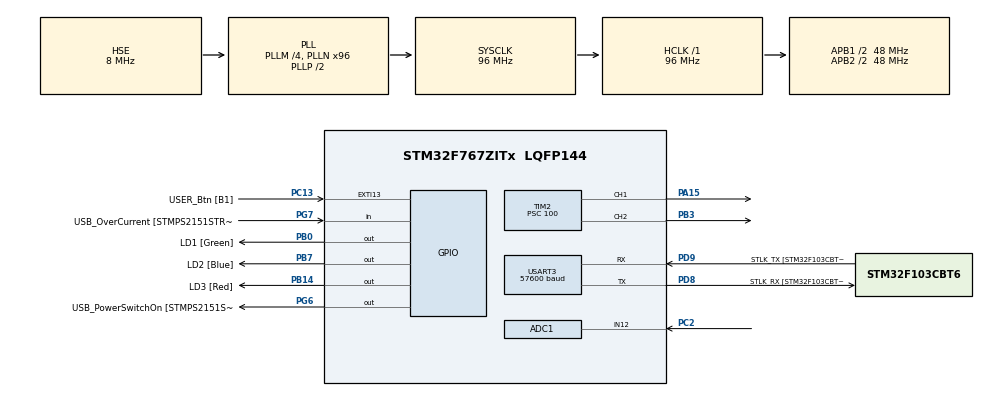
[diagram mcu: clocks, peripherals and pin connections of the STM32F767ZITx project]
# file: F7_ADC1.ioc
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ADC1.Channel-0\#ChannelRegularConversion=ADC_CHANNEL_12
ADC1.Channel-1\#ChannelRegularConversion=ADC_CHANNEL_TEMPSENSOR
ADC1.DMAContinuousRequests=ENABLE
ADC1.EOCSelection=ADC_EOC_SEQ_CONV
ADC1.ExternalTrigConv=ADC_EXTERNALTRIGCONV_T1_TRGO
ADC1.NbrOfConversion=2
ADC1.NbrOfConversionFlag=1
ADC1.Rank-0\#ChannelRegularConversion=1
ADC1.Rank-1\#ChannelRegularConversion=2
ADC1.SamplingTime-0\#ChannelRegularConversion=ADC_SAMPLETIME_480CYCLES
ADC1.SamplingTime-1\#ChannelRegularConversion=ADC_SAMPLETIME_480CYCLES
ADC1.master=1
Dma.ADC1.0.Direction=DMA_PERIPH_TO_MEMORY
Dma.ADC1.0.FIFOMode=DMA_FIFOMODE_DISABLE
Dma.ADC1.0.Instance=DMA2_Stream0
Dma.ADC1.0.MemDataAlignment=DMA_MDATAALIGN_WORD
Dma.ADC1.0.MemInc=DMA_MINC_ENABLE
Dma.ADC1.0.Mode=DMA_CIRCULAR
Dma.ADC1.0.PeriphDataAlignment=DMA_PDATAALIGN_WORD
Dma.ADC1.0.PeriphInc=DMA_PINC_DISABLE
Dma.ADC1.0.Priority=DMA_PRIORITY_LOW
Dma.Request0=ADC1
Mcu.Family=STM32F7
Mcu.Name=STM32F767ZITx
Mcu.Package=LQFP144
NVIC.DMA2_Stream0_IRQn=true\:0\:0\:false\:false\:true\:false\:true\:true
NVIC.PriorityGroup=NVIC_PRIORITYGROUP_4
NVIC.USART3_IRQn=true\:0\:0\:false\:false\:true\:true\:true\:true
PA13.GPIO_Label=TMS
PA13.Mode=Serial_Wire
PA13.Signal=SYS_JTMS-SWDIO
PA14.GPIO_Label=TCK
PA14.Mode=Serial_Wire
PA14.Signal=SYS_JTCK-SWCLK
PA15.Signal=S_TIM2_CH1_ETR
PB0.GPIO_Label=LD1 [Green]
PB0.Signal=GPIO_Output
PB14.GPIO_Label=LD3 [Red]
PB14.Signal=GPIO_Output
PB3.Signal=S_TIM2_CH2
PB7.GPIO_Label=LD2 [Blue]
PB7.Signal=GPIO_Output
PC13.GPIO_Label=USER_Btn [B1]
PC13.Signal=GPXTI13
PC14/OSC32_IN.Mode=LSE-External-Oscillator
PC14/OSC32_IN.Signal=RCC_OSC32_IN
PC15/OSC32_OUT.Mode=LSE-External-Oscillator
PC15/OSC32_OUT.Signal=RCC_OSC32_OUT
PC2.Signal=ADCx_IN12
PD8.GPIO_Label=STLK_RX [STM32F103CBT6_PA3]
PD8.Mode=Asynchronous
PD8.Signal=USART3_TX
PD9.GPIO_Label=STLK_TX [STM32F103CBT6_PA2]
PD9.Mode=Asynchronous
PD9.Signal=USART3_RX
PG6.GPIO_Label=USB_PowerSwitchOn [STMPS2151STR_EN]
PG6.Signal=GPIO_Output
PG7.GPIO_Label=USB_OverCurrent [STMPS2151STR_FAULT]
PG7.Signal=GPIO_Input
PH0/OSC_IN.GPIO_Label=MCO [STM32F103CBT6_PA8]
PH0/OSC_IN.Mode=HSE-External-Clock-Source
PH0/OSC_IN.Signal=RCC_OSC_IN
PH1/OSC_OUT.Mode=HSE-External-Clock-Source
PH1/OSC_OUT.Signal=RCC_OSC_OUT
ProjectManager.HeapSize=0x200
ProjectManager.StackSize=0x400
ProjectManager.TargetToolchain=STM32CubeIDE
RCC.48MHZClocksFreq_Value=24000000
RCC.AHBFreq_Value=96000000
RCC.APB1CLKDivider=RCC_HCLK_DIV2
RCC.APB1Freq_Value=48000000
RCC.APB1TimFreq_Value=96000000
RCC.APB2CLKDivider=RCC_HCLK_DIV2
RCC.APB2Freq_Value=48000000
RCC.APB2TimFreq_Value=96000000
RCC.CortexFreq_Value=96000000
RCC.HCLKFreq_Value=96000000
RCC.HSE_VALUE=8000000
RCC.HSI_VALUE=16000000
RCC.PLLM=4
RCC.PLLMUL=RCC_PLL_MUL9
RCC.PLLN=96
RCC.PLLQ=4
RCC.PLLSourceVirtual=RCC_PLLSOURCE_HSE
RCC.PRESCALERUSB=RCC_USBCLKSOURCE_PLL_DIV1_5
RCC.SYSCLKFreq_VALUE=96000000
RCC.SYSCLKSource=RCC_SYSCLKSOURCE_PLLCLK
RCC.SYSCLKSourceVirtual=RCC_SYSCLKSOURCE_PLLCLK
RCC.USBFreq_Value=48000000
RCC.VCOOutputFreq_Value=192000000
SH.ADCx_IN12.0=ADC1_IN12,IN12
SH.S_TIM2_CH1_ETR.0=TIM2_CH1,PWM Generation1 CH1
SH.S_TIM2_CH2.0=TIM2_CH2,PWM Generation2 CH2
TIM1.Channel-Output\ Compare1\ No\ Output=TIM_CHANNEL_1
TIM1.Period=49
TIM1.Prescaler=48000
TIM1.TIM_MasterOutputTrigger=TIM_TRGO_UPDATE
TIM2.AutoReloadPreload=TIM_AUTORELOAD_PRELOAD_DISABLE
TIM2.Channel-PWM\ Generation1\ CH1=TIM_CHANNEL_1
TIM2.Channel-PWM\ Generation2\ CH2=TIM_CHANNEL_2
TIM2.OC1Preload_PWM=DISABLE
TIM2.OC2Preload_PWM=DISABLE
TIM2.OCFastMode_PWM-PWM\ Generation1\ CH1=TIM_OCFAST_DISABLE
TIM2.OCFastMode_PWM-PWM\ Generation2\ CH2=TIM_OCFAST_DISABLE
TIM2.Period=999
TIM2.Prescaler=100
TIM2.Pulse-PWM\ Generation1\ CH1=0
TIM2.Pulse-PWM\ Generation2\ CH2=0
USART3.BaudRate=57600
USART3.VirtualMode-Asynchronous=VM_ASYNC
VP_ADC1_TempSens_Input.Mode=IN-TempSens
VP_TIM1_VS_ClockSourceINT.Mode=Internal
VP_TIM1_VS_no_output1.Mode=Output Compare1 No Output
VP_TIM2_VS_ClockSourceINT.Mode=Internal
board=NUCLEO-F767ZI

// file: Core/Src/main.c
/* USER CODE BEGIN Header */
/**
  ******************************************************************************
  * @file           : main.c
  * @brief          : Main program body
  ******************************************************************************
  * @attention
  *
  * Copyright (c) 2023 STMicroelectronics.
  * All rights reserved.
  *
  * This software is licensed under terms that can be found in the LICENSE file
  * in the root directory of this software component.
  * If no LICENSE file comes with this software, it is provided AS-IS.
  *
  ******************************************************************************
  */
/* USER CODE END Header */
#include "main.h"
#include "adc.h"
#include "dma.h"
#include "tim.h"
#include "usart.h"
#include "gpio.h"

/* USER CODE BEGIN Includes */
#include <stdio.h>
#include <string.h>

#include "app_interface.h"

/* USER CODE END Includes */

void SystemClock_Config(void);

int main(void)
{

  /* MCU Configuration--------------------------------------------------------*/

  /* Reset of all peripherals, Initializes the Flash interface and the Systick. */
  HAL_Init();

  /* Configure the system clock */
  SystemClock_Config();

  /* Initialize all configured peripherals */
  MX_GPIO_Init();
  MX_DMA_Init();
  MX_USART3_UART_Init();
  MX_ADC1_Init();
  MX_TIM1_Init();
  MX_TIM2_Init();
  /* USER CODE BEGIN 2 */
  noreturn_app();
  /* USER CODE END 2 */

  /* Infinite loop */
  while (1)
  {

  }
}

void SystemClock_Config(void)
{
  RCC_OscInitTypeDef RCC_OscInitStruct = {0};
  RCC_ClkInitTypeDef RCC_ClkInitStruct = {0};

  /** Configure LSE Drive Capability
  */
  HAL_PWR_EnableBkUpAccess();

  /** Configure the main internal regulator output voltage
  */
  __HAL_RCC_PWR_CLK_ENABLE();
  __HAL_PWR_VOLTAGESCALING_CONFIG(PWR_REGULATOR_VOLTAGE_SCALE3);

  /** Initializes the RCC Oscillators according to the specified parameters
  * in the RCC_OscInitTypeDef structure.
  */
  RCC_OscInitStruct.OscillatorType = RCC_OSCILLATORTYPE_HSE;
  RCC_OscInitStruct.HSEState = RCC_HSE_BYPASS;
  RCC_OscInitStruct.PLL.PLLState = RCC_PLL_ON;
  RCC_OscInitStruct.PLL.PLLSource = RCC_PLLSOURCE_HSE;
  RCC_OscInitStruct.PLL.PLLM = 4;
  RCC_OscInitStruct.PLL.PLLN = 96;
  RCC_OscInitStruct.PLL.PLLP = RCC_PLLP_DIV2;
  RCC_OscInitStruct.PLL.PLLQ = 4;
  RCC_OscInitStruct.PLL.PLLR = 2;
  if (HAL_RCC_OscConfig(&RCC_OscInitStruct) != HAL_OK)
  {
    Error_Handler();
  }

  /** Activate the Over-Drive mode
  */
  if (HAL_PWREx_EnableOverDrive() != HAL_OK)
  {
    Error_Handler();
  }

  /** Initializes the CPU, AHB and APB buses clocks
  */
  RCC_ClkInitStruct.ClockType = RCC_CLOCKTYPE_HCLK|RCC_CLOCKTYPE_SYSCLK
                              |RCC_CLOCKTYPE_PCLK1|RCC_CLOCKTYPE_PCLK2;
  RCC_ClkInitStruct.SYSCLKSource = RCC_SYSCLKSOURCE_PLLCLK;
  RCC_ClkInitStruct.AHBCLKDivider = RCC_SYSCLK_DIV1;
  RCC_ClkInitStruct.APB1CLKDivider = RCC_HCLK_DIV2;
  RCC_ClkInitStruct.APB2CLKDivider = RCC_HCLK_DIV2;

  if (HAL_RCC_ClockConfig(&RCC_ClkInitStruct, FLASH_LATENCY_3) != HAL_OK)
  {
    Error_Handler();
  }
}

/* USER CODE BEGIN 4 */

void HAL_UART_RxCpltCallback(UART_HandleTypeDef *huart)
{
	uart_cb(huart);
}

void HAL_ADC_ConvCpltCallback(ADC_HandleTypeDef* hadc)
{
	adc_cb(hadc);
}

int _write(int file, char *ptr, int len)
{
	HAL_UART_Transmit(&huart3, (uint8_t*)ptr, len, HAL_MAX_DELAY);
	return len;
}

/* USER CODE END 4 */

void Error_Handler(void)
{
  __disable_irq();
  while (1)
  {
  }
}
